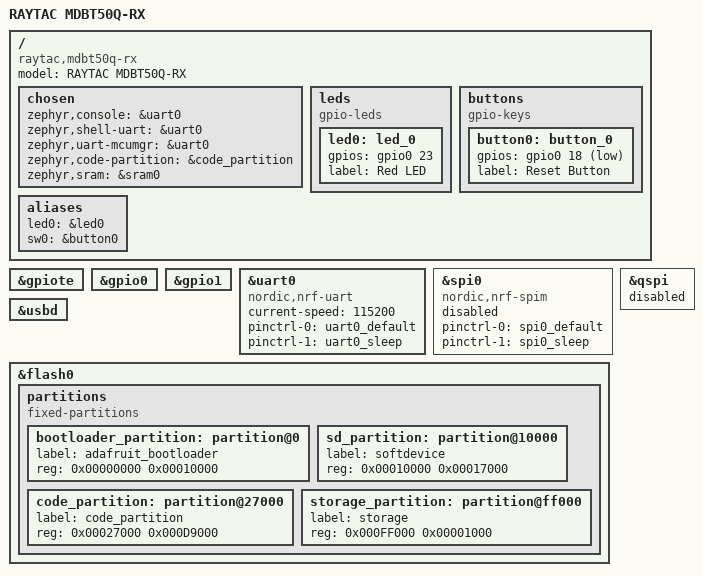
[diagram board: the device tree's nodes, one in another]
/*
 * Copyright (c) 2024
 * SPDX-License-Identifier: Apache-2.0
 */

/dts-v1/;
#include <nordic/nrf52840_qiaa.dtsi>
#include "mdbt50q_rx-pinctrl.dtsi"

/ {
	model = "RAYTAC MDBT50Q-RX";
	compatible = "raytac,mdbt50q-rx";

	chosen {
		zephyr,console = &uart0;
		zephyr,shell-uart = &uart0;
		zephyr,uart-mcumgr = &uart0;
		zephyr,code-partition = &code_partition;
		zephyr,sram = &sram0;
	};

	leds {
		compatible = "gpio-leds";
		led0: led_0 {
			gpios = <&gpio0 23 GPIO_ACTIVE_HIGH>;
			label = "Red LED";
		};
	};

	buttons {
		compatible = "gpio-keys";
		button0: button_0 {
			gpios = <&gpio0 18 (GPIO_PULL_UP | GPIO_ACTIVE_LOW)>;
			label = "Reset Button";
		};
	};

	aliases {
		led0 = &led0;
		sw0 = &button0;
	};
};

&gpiote {
	status = "okay";
};

&gpio0 {
	status = "okay";
};

&gpio1 {
	status = "okay";
};

&uart0 {
	compatible = "nordic,nrf-uart";
	status = "okay";
	current-speed = <115200>;
	pinctrl-0 = <&uart0_default>;
	pinctrl-1 = <&uart0_sleep>;
	pinctrl-names = "default", "sleep";
};

&spi0 {
	compatible = "nordic,nrf-spim";
	status = "disabled";
	pinctrl-0 = <&spi0_default>;
	pinctrl-1 = <&spi0_sleep>;
	pinctrl-names = "default", "sleep";
};

&qspi {
	status = "disabled";
};

&usbd {
	status = "okay";
};

&flash0 {
	partitions {
		compatible = "fixed-partitions";
		#address-cells = <1>;
		#size-cells = <1>;

		bootloader_partition: partition@0 {
			label = "adafruit_bootloader";
			reg = <0x00000000 0x00010000>;
		};

		sd_partition: partition@10000 {
			label = "softdevice";
			reg = <0x00010000 0x00017000>;
		};

		code_partition: partition@27000 {
			label = "code_partition";
			reg = <0x00027000 0x000D9000>;
		};

		storage_partition: partition@ff000 {
			label = "storage";
			reg = <0x000FF000 0x00001000>;
		};
	};
};
